# STM32F303RDT6 register map
File version: 1.0
Registers are 32-bit, access not given, reset 0x0 unless marked. A register's access mark holds for its fields unless they carry their own. Offsets are from the block's base; [hi:lo] are bit positions; {n}, {i} and the like mark numbered series.

## CANSRAM
Base 0x40006000
Same registers: CAN 0x40006400
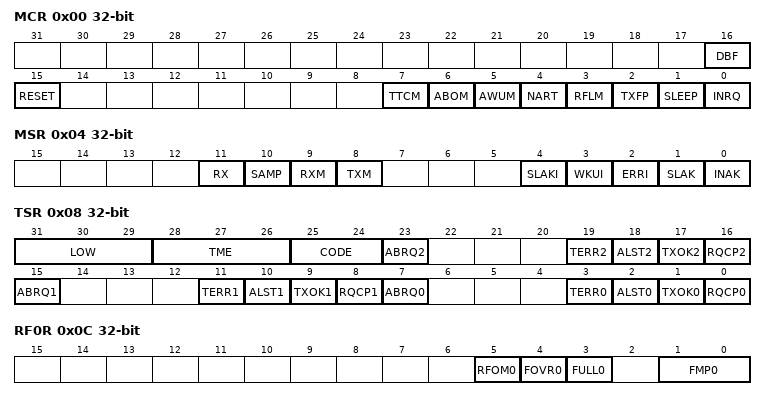
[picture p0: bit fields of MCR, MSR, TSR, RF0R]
0x00 MCR
  [16] DBF, [15] RESET, [7] TTCM, [6] ABOM, [5] AWUM, [4] NART, [3] RFLM, [2] TXFP, [1] SLEEP, [0] INRQ
0x04 MSR
  [11] RX, [10] SAMP, [9] RXM, [8] TXM, [4] SLAKI, [3] WKUI, [2] ERRI, [1] SLAK, [0] INAK
0x08 TSR
  [31:29] LOW, [28:26] TME, [25:24] CODE, [23] ABRQ2, [19] TERR2, [18] ALST2, [17] TXOK2, [16] RQCP2, [15] ABRQ1, [11] TERR1, [10] ALST1, [9] TXOK1, [8] RQCP1, [7] ABRQ0, [3] TERR0, [2] ALST0, [1] TXOK0, [0] RQCP0
0x0C RF0R
  [5] RFOM0, [4] FOVR0, [3] FULL0, [1:0] FMP0
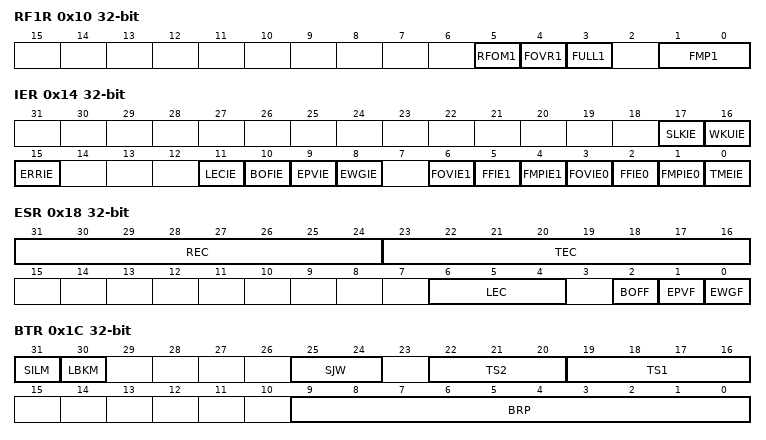
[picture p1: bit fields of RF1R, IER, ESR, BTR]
0x10 RF1R
  [5] RFOM1, [4] FOVR1, [3] FULL1, [1:0] FMP1
0x14 IER
  [17] SLKIE, [16] WKUIE, [15] ERRIE, [11] LECIE, [10] BOFIE, [9] EPVIE, [8] EWGIE, [6] FOVIE1, [5] FFIE1, [4] FMPIE1, [3] FOVIE0, [2] FFIE0, [1] FMPIE0, [0] TMEIE
0x18 ESR
  [31:24] REC, [23:16] TEC, [6:4] LEC, [2] BOFF, [1] EPVF, [0] EWGF
0x1C BTR
  [31] SILM, [30] LBKM, [25:24] SJW, [22:20] TS2, [19:16] TS1, [9:0] BRP
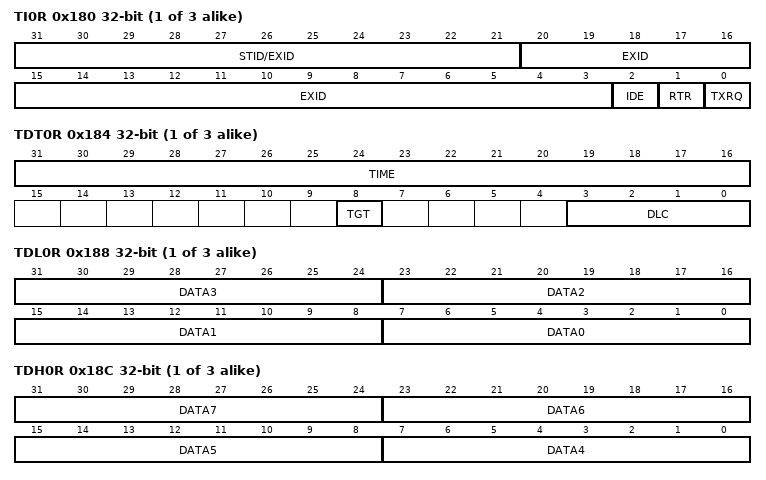
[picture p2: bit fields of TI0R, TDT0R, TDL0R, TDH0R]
{0x180+0x10*i} TI{i}R (i=0..2)
  [31:21] STID/EXID, [20:3] EXID, [2] IDE, [1] RTR, [0] TXRQ
{0x184+0x10*i} TDT{i}R (i=0..2)
  [31:16] TIME, [8] TGT, [3:0] DLC
{0x188+0x10*i} TDL{i}R (i=0..2)
  [8n+7:8n] DATA{n} (n=0..3)
{0x18C+0x10*i} TDH{i}R (i=0..2)
  [8n-25:8n-32] DATA{n} (n=4..7)
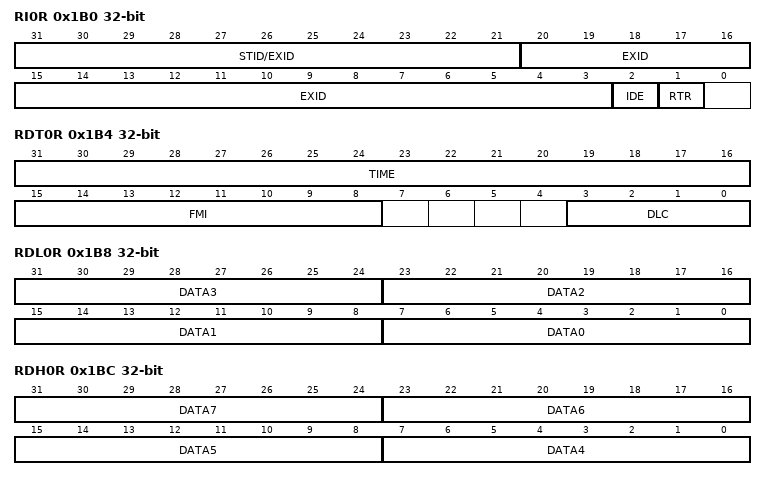
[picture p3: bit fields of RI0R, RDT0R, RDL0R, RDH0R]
0x1B0 RI0R
  [31:21] STID/EXID, [20:3] EXID, [2] IDE, [1] RTR
0x1B4 RDT0R
  [31:16] TIME, [15:8] FMI, [3:0] DLC
0x1B8 RDL0R
  [8n+7:8n] DATA{n} (n=0..3)
0x1BC RDH0R
  [8n-25:8n-32] DATA{n} (n=4..7)
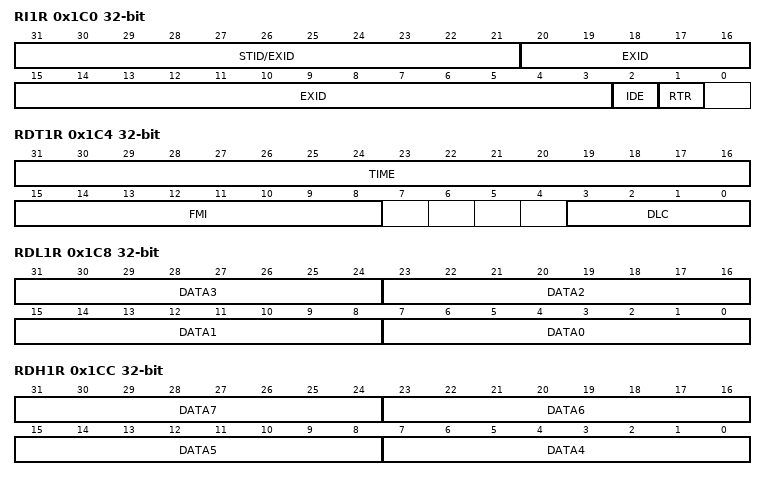
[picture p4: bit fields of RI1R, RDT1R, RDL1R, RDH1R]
0x1C0 RI1R
  [31:21] STID/EXID, [20:3] EXID, [2] IDE, [1] RTR
0x1C4 RDT1R
  [31:16] TIME, [15:8] FMI, [3:0] DLC
0x1C8 RDL1R
  [8n+7:8n] DATA{n} (n=0..3)
0x1CC RDH1R
  [8n-25:8n-32] DATA{n} (n=4..7)
0x200 FMR
  [0] FINIT
0x204 FM1R
  [13:0] FBM
0x20C FS1R
  [13:0] FSC
0x214 FFA1R
  [13:0] FFA
0x21C FA1R
  [13:0] FACT
{0x240+8i} F{i}R1 (i=0..27)
  [31:0] FB
{0x244+8i} F{i}R2 (i=0..27)
  [31:0] FB

## PWR
Base 0x40007000
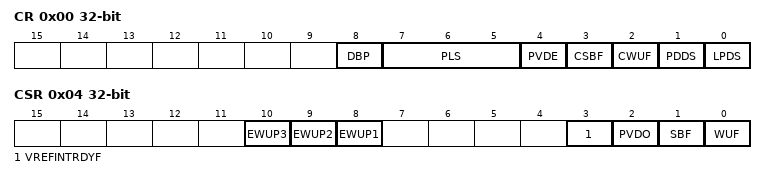
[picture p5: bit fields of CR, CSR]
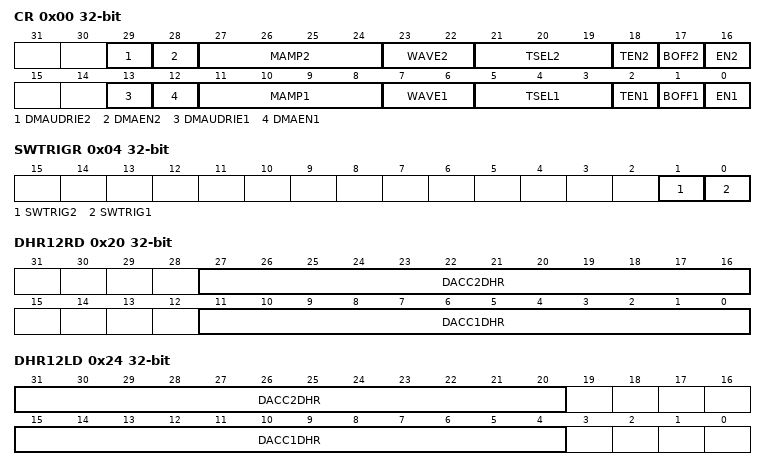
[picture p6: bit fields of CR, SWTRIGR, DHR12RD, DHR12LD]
0x00 CR
  [8] DBP, [7:5] PLS, [4] PVDE, [3] CSBF, [2] CWUF, [1] PDDS, [0] LPDS
0x04 CSR
  [10] EWUP3, [9] EWUP2, [8] EWUP1, [3] VREFINTRDYF, [2] PVDO, [1] SBF, [0] WUF

## DAC1
Base 0x40007400
0x00 CR
  [29] DMAUDRIE2, [28] DMAEN2, [27:24] MAMP2, [23:22] WAVE2, [21:19] TSEL2, [18] TEN2, [17] BOFF2, [16] EN2, [13] DMAUDRIE1, [12] DMAEN1, [11:8] MAMP1, [7:6] WAVE1, [5:3] TSEL1, [2] TEN1, [1] BOFF1, [0] EN1
0x04 SWTRIGR
  [1] SWTRIG2, [0] SWTRIG1
0x08 DHR12R1
  [11:0] DACC1DHR
0x0C DHR12L1
  [15:4] DACC1DHR
0x10 DHR8R1
  [7:0] DACC1DHR
0x14 DHR12R2
  [11:0] DACC2DHR
0x18 DHR12L2
  [15:4] DACC2DHR
0x1C DHR8R2
  [7:0] DACC2DHR
0x20 DHR12RD
  [27:16] DACC2DHR, [11:0] DACC1DHR
0x24 DHR12LD
  [31:20] DACC2DHR, [15:4] DACC1DHR
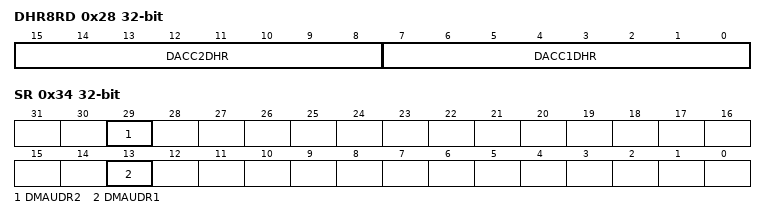
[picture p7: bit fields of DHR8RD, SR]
0x28 DHR8RD
  [15:8] DACC2DHR, [7:0] DACC1DHR
0x2C DOR1
  [11:0] DACC1DOR
0x30 DOR2
  [11:0] DACC2DOR
0x34 SR
  [29] DMAUDR2, [13] DMAUDR1

## SYSCFG
Base 0x40010000
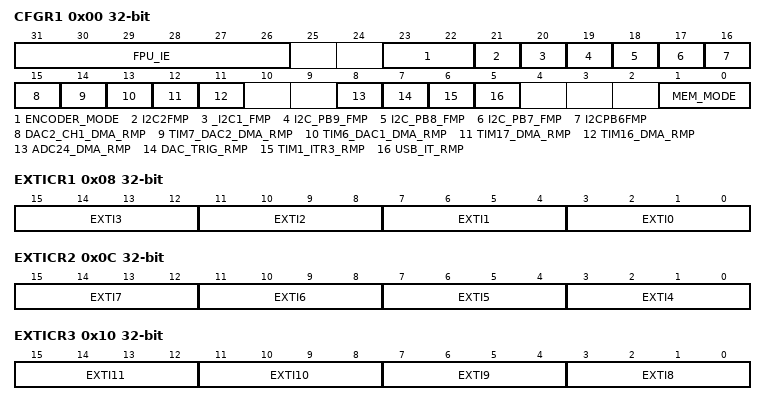
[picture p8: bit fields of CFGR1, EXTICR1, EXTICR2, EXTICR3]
0x00 CFGR1
  [31:26] FPU_IE, [23:22] ENCODER_MODE, [21] I2C2FMP, [20] _I2C1_FMP, [19] I2C_PB9_FMP, [18] I2C_PB8_FMP, [17] I2C_PB7_FMP, [16] I2CPB6FMP, [15] DAC2_CH1_DMA_RMP, [14] TIM7_DAC2_DMA_RMP, [13] TIM6_DAC1_DMA_RMP, [12] TIM17_DMA_RMP, [11] TIM16_DMA_RMP, [8] ADC24_DMA_RMP, [7] DAC_TRIG_RMP, [6] TIM1_ITR3_RMP, [5] USB_IT_RMP, [1:0] MEM_MODE
0x04 RCR
  [14:0] PAGE_WP
0x08 EXTICR1
  [4n+3:4n] EXTI{n} (n=0..3)
0x0C EXTICR2
  [4n-13:4n-16] EXTI{n} (n=4..7)
0x10 EXTICR3
  [4n-29:4n-32] EXTI{n} (n=8..11)
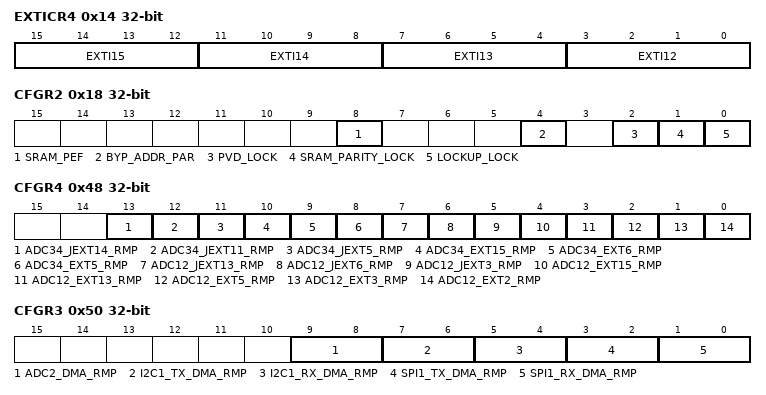
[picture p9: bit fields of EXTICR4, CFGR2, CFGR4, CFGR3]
0x14 EXTICR4
  [4n-45:4n-48] EXTI{n} (n=12..15)
0x18 CFGR2
  [8] SRAM_PEF, [4] BYP_ADDR_PAR, [2] PVD_LOCK, [1] SRAM_PARITY_LOCK, [0] LOCKUP_LOCK
0x48 CFGR4
  [13] ADC34_JEXT14_RMP, [12] ADC34_JEXT11_RMP, [11] ADC34_JEXT5_RMP, [10] ADC34_EXT15_RMP, [9] ADC34_EXT6_RMP, [8] ADC34_EXT5_RMP, [7] ADC12_JEXT13_RMP, [6] ADC12_JEXT6_RMP, [5] ADC12_JEXT3_RMP, [4] ADC12_EXT15_RMP, [3] ADC12_EXT13_RMP, [2] ADC12_EXT5_RMP, [1] ADC12_EXT3_RMP, [0] ADC12_EXT2_RMP
0x50 CFGR3
  [9:8] ADC2_DMA_RMP, [7:6] I2C1_TX_DMA_RMP, [5:4] I2C1_RX_DMA_RMP, [3:2] SPI1_TX_DMA_RMP, [1:0] SPI1_RX_DMA_RMP
